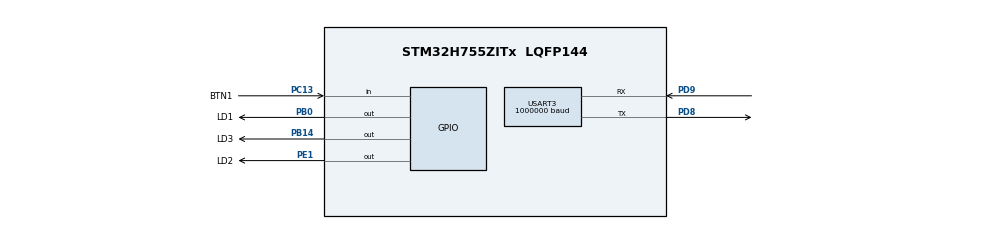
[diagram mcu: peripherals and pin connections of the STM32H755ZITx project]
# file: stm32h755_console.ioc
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CORTEX_M7.default_mode_Activation=1
CortexM4.IPs=CORTEX_M4\:I,FATFS_M4\:I,FREERTOS_M4\:I,IWDG2\:I,OPENAMP_M4\:I,PDM2PCM_M4\:I,PWR,RCC,RESMGR_UTILITY,SYS_M4\:I,USB_DEVICE_M4\:I,USB_HOST_M4\:I,VREFBUF,WWDG2\:I,GPIO,DMA,BDMA,MDMA,NVIC2\:I
CortexM7.IPs=CORTEX_M7\:I,FATFS_M7\:I,FREERTOS_M7\:I,IWDG1\:I,OPENAMP_M7\:I,PDM2PCM_M7\:I,PWR\:I,RCC\:I,RESMGR_UTILITY\:I,SYS\:I,USB_DEVICE_M7\:I,USB_HOST_M7\:I,VREFBUF\:I,WWDG1\:I,GPIO\:I,DMA\:I,BDMA\:I,MDMA\:I,NVIC1\:I,USART3\:I,TIM1\:I,TIM2\:I
CortexM7.Pins=PC13,PB0,PB14,PE1
Dma.Request0=USART3_TX
Dma.USART3_TX.0.Instance=DMA1_Stream0
Dma.USART3_TX.0.Direction=DMA_MEMORY_TO_PERIPH
Dma.USART3_TX.0.PeriphInc=DMA_PINC_DISABLE
Dma.USART3_TX.0.MemInc=DMA_MINC_ENABLE
Dma.USART3_TX.0.PeriphDataAlignment=DMA_PDATAALIGN_BYTE
Dma.USART3_TX.0.MemDataAlignment=DMA_MDATAALIGN_BYTE
Dma.USART3_TX.0.Mode=DMA_NORMAL
Dma.USART3_TX.0.Priority=DMA_PRIORITY_LOW
Dma.USART3_TX.0.FIFOMode=DMA_FIFOMODE_DISABLE
Mcu.Family=STM32H7
Mcu.Name=STM32H755ZITx
Mcu.Package=LQFP144
NVIC1.DMA1_Stream0_IRQn=true\:5\:0\:false\:false\:true\:true\:true\:true
NVIC1.FPU_IRQn=true\:0\:0\:false\:false\:true\:true\:false\:true
NVIC1.PriorityGroup=NVIC_PRIORITYGROUP_4
NVIC1.RCC_IRQn=true\:0\:0\:false\:false\:true\:true\:false\:true
NVIC1.USART3_IRQn=true\:0\:0\:false\:false\:true\:true\:true\:true
NVIC2.PriorityGroup=NVIC_PRIORITYGROUP_4
PB0.GPIO_Label=LD1
PB0.PinAttribute=CortexM7
PB0.Signal=GPIO_Output
PB14.GPIO_Label=LD3
PB14.PinAttribute=CortexM7
PB14.Signal=GPIO_Output
PC13.GPIO_Label=BTN1
PC13.PinAttribute=CortexM7
PC13.Signal=GPIO_Input
PD8.Mode=Asynchronous
PD8.PinAttribute=CortexM7
PD8.Signal=USART3_TX
PD9.Mode=Asynchronous
PD9.PinAttribute=CortexM7
PD9.Signal=USART3_RX
PE1.GPIO_Label=LD2
PE1.PinAttribute=CortexM7
PE1.Signal=GPIO_Output
ProjectManager.HeapSize=M4-0x200,M7-0x200
ProjectManager.StackSize=M4-0x400,M7-0x4000
ProjectManager.TargetToolchain=CMake
RCC.ADCFreq_Value=32000000
RCC.APB1Freq_Value=25000000
RCC.APB2Freq_Value=50000000
RCC.APB3Freq_Value=50000000
RCC.APB4Freq_Value=50000000
RCC.CortexFreq_Value=400000000
RCC.D2PPRE1=RCC_APB1_DIV2
RCC.DIVM1=4
RCC.DIVM2=4
RCC.DIVM3=4
RCC.DIVN1=50
RCC.DIVN2=16
RCC.DIVN3=16
RCC.HSE_VALUE=8000000
RCC.HCLKFreq_Value=50000000
RCC.HPRE=RCC_HCLK_DIV8
RCC.PLLSourceVirtual=RCC_PLLSOURCE_HSI
RCC.SYSCLKFreq_VALUE=400000000
RCC.SYSCLKSource=RCC_SYSCLKSOURCE_PLLCLK
RCC.USBFreq_Value=400000000
SYS.userName=SYS_M7
USART3.BaudRate=1000000
USART3.VirtualMode-Asynchronous=VM_ASYNC
VP_SYS_M4_VS_Systick.Mode=SysTick
board=custom

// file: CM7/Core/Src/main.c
/* USER CODE BEGIN Header */
/**
  ******************************************************************************
  * @file           : main.c
  * @brief          : Main program body
  ******************************************************************************
  * @attention
  *
  * Copyright (c) 2026 STMicroelectronics.
  * All rights reserved.
  *
  * This software is licensed under terms that can be found in the LICENSE file
  * in the root directory of this software component.
  * If no LICENSE file comes with this software, it is provided AS-IS.
  *
  ******************************************************************************
  */
/* USER CODE END Header */
#include "main.h"

/* USER CODE BEGIN PD */

/* DUAL_CORE_BOOT_SYNC_SEQUENCE: Define for dual core boot synchronization    */
/*                             demonstration code based on hardware semaphore */
/* This define is present in both CM7/CM4 projects                            */
/* To comment when developping/debugging on a single core                     */
#define DUAL_CORE_BOOT_SYNC_SEQUENCE

#if defined(DUAL_CORE_BOOT_SYNC_SEQUENCE)
#ifndef HSEM_ID_0
#define HSEM_ID_0 (0U) /* HW semaphore 0*/
#endif
#endif /* DUAL_CORE_BOOT_SYNC_SEQUENCE */

/* USER CODE END PD */

UART_HandleTypeDef huart3;

void SystemClock_Config(void);
static void MPU_Config(void);
static void MX_GPIO_Init(void);
static void MX_DMA_Init(void);
static void MX_USART3_UART_Init(void);
/* USER CODE BEGIN PFP */
void DaveOS_Run(void);

/* USER CODE END PFP */

int main(void)
{

/* USER CODE BEGIN Boot_Mode_Sequence_0 */
#if defined(DUAL_CORE_BOOT_SYNC_SEQUENCE)
  int32_t timeout;
#endif /* DUAL_CORE_BOOT_SYNC_SEQUENCE */
/* USER CODE END Boot_Mode_Sequence_0 */

  /* MPU Configuration--------------------------------------------------------*/
  MPU_Config();

/* USER CODE BEGIN Boot_Mode_Sequence_1 */
#if defined(DUAL_CORE_BOOT_SYNC_SEQUENCE)
  /* Wait until CPU2 boots and enters in stop mode or timeout*/
  timeout = 0xFFFF;
  while((__HAL_RCC_GET_FLAG(RCC_FLAG_D2CKRDY) != RESET) && (timeout-- > 0));
  if ( timeout < 0 )
  {
  Error_Handler();
  }
#endif /* DUAL_CORE_BOOT_SYNC_SEQUENCE */
/* USER CODE END Boot_Mode_Sequence_1 */
  /* MCU Configuration--------------------------------------------------------*/

  /* Reset of all peripherals, Initializes the Flash interface and the Systick. */
  HAL_Init();

  /* Configure the system clock */
  SystemClock_Config();
/* USER CODE BEGIN Boot_Mode_Sequence_2 */
#if defined(DUAL_CORE_BOOT_SYNC_SEQUENCE)
/* When system initialization is finished, Cortex-M7 will release Cortex-M4 by means of
HSEM notification */
/*HW semaphore Clock enable*/
__HAL_RCC_HSEM_CLK_ENABLE();
/*Take HSEM */
HAL_HSEM_FastTake(HSEM_ID_0);
/*Release HSEM in order to notify the CPU2(CM4)*/
HAL_HSEM_Release(HSEM_ID_0,0);
/* wait until CPU2 wakes up from stop mode */
timeout = 0xFFFF;
while((__HAL_RCC_GET_FLAG(RCC_FLAG_D2CKRDY) == RESET) && (timeout-- > 0));
if ( timeout < 0 )
{
Error_Handler();
}
#endif /* DUAL_CORE_BOOT_SYNC_SEQUENCE */
/* USER CODE END Boot_Mode_Sequence_2 */

  /* Initialize all configured peripherals */
  MX_GPIO_Init();
  MX_DMA_Init();
  MX_USART3_UART_Init();
  /* USER CODE BEGIN 2 */
  DaveOS_Run();

  /* USER CODE END 2 */

  /* Infinite loop */
  while (1)
  {

  }
}

void SystemClock_Config(void)
{
  RCC_OscInitTypeDef RCC_OscInitStruct = {0};
  RCC_ClkInitTypeDef RCC_ClkInitStruct = {0};

  /** Supply configuration update enable
  */
  HAL_PWREx_ConfigSupply(PWR_DIRECT_SMPS_SUPPLY);

  /** Configure the main internal regulator output voltage
  */
  __HAL_PWR_VOLTAGESCALING_CONFIG(PWR_REGULATOR_VOLTAGE_SCALE1);

  while(!__HAL_PWR_GET_FLAG(PWR_FLAG_VOSRDY)) {}

  /** Initializes the RCC Oscillators according to the specified parameters
  * in the RCC_OscInitTypeDef structure.
  */
  RCC_OscInitStruct.OscillatorType = RCC_OSCILLATORTYPE_HSI;
  RCC_OscInitStruct.HSIState = RCC_HSI_DIV1;
  RCC_OscInitStruct.HSICalibrationValue = RCC_HSICALIBRATION_DEFAULT;
  RCC_OscInitStruct.PLL.PLLState = RCC_PLL_ON;
  RCC_OscInitStruct.PLL.PLLSource = RCC_PLLSOURCE_HSI;
  RCC_OscInitStruct.PLL.PLLM = 4;
  RCC_OscInitStruct.PLL.PLLN = 50;
  RCC_OscInitStruct.PLL.PLLP = 2;
  RCC_OscInitStruct.PLL.PLLQ = 2;
  RCC_OscInitStruct.PLL.PLLR = 2;
  RCC_OscInitStruct.PLL.PLLRGE = RCC_PLL1VCIRANGE_3;
  RCC_OscInitStruct.PLL.PLLVCOSEL = RCC_PLL1VCOWIDE;
  RCC_OscInitStruct.PLL.PLLFRACN = 0;
  if (HAL_RCC_OscConfig(&RCC_OscInitStruct) != HAL_OK)
  {
    Error_Handler();
  }

  /** Initializes the CPU, AHB and APB buses clocks
  */
  RCC_ClkInitStruct.ClockType = RCC_CLOCKTYPE_HCLK|RCC_CLOCKTYPE_SYSCLK
                              |RCC_CLOCKTYPE_PCLK1|RCC_CLOCKTYPE_PCLK2
                              |RCC_CLOCKTYPE_D3PCLK1|RCC_CLOCKTYPE_D1PCLK1;
  RCC_ClkInitStruct.SYSCLKSource = RCC_SYSCLKSOURCE_PLLCLK;
  RCC_ClkInitStruct.SYSCLKDivider = RCC_SYSCLK_DIV1;
  RCC_ClkInitStruct.AHBCLKDivider = RCC_HCLK_DIV8;
  RCC_ClkInitStruct.APB3CLKDivider = RCC_APB3_DIV1;
  RCC_ClkInitStruct.APB1CLKDivider = RCC_APB1_DIV2;
  RCC_ClkInitStruct.APB2CLKDivider = RCC_APB2_DIV1;
  RCC_ClkInitStruct.APB4CLKDivider = RCC_APB4_DIV1;

  if (HAL_RCC_ClockConfig(&RCC_ClkInitStruct, FLASH_LATENCY_0) != HAL_OK)
  {
    Error_Handler();
  }
}

static void MX_USART3_UART_Init(void)
{

  huart3.Instance = USART3;
  huart3.Init.BaudRate = 1000000;
  huart3.Init.WordLength = UART_WORDLENGTH_8B;
  huart3.Init.StopBits = UART_STOPBITS_1;
  huart3.Init.Parity = UART_PARITY_NONE;
  huart3.Init.Mode = UART_MODE_TX_RX;
  huart3.Init.HwFlowCtl = UART_HWCONTROL_NONE;
  huart3.Init.OverSampling = UART_OVERSAMPLING_16;
  huart3.Init.OneBitSampling = UART_ONE_BIT_SAMPLE_DISABLE;
  huart3.Init.ClockPrescaler = UART_PRESCALER_DIV1;
  huart3.AdvancedInit.AdvFeatureInit = UART_ADVFEATURE_NO_INIT;
  if (HAL_UART_Init(&huart3) != HAL_OK)
  {
    Error_Handler();
  }
  if (HAL_UARTEx_SetTxFifoThreshold(&huart3, UART_TXFIFO_THRESHOLD_1_8) != HAL_OK)
  {
    Error_Handler();
  }
  if (HAL_UARTEx_SetRxFifoThreshold(&huart3, UART_RXFIFO_THRESHOLD_1_8) != HAL_OK)
  {
    Error_Handler();
  }
  if (HAL_UARTEx_DisableFifoMode(&huart3) != HAL_OK)
  {
    Error_Handler();
  }

}

static void MX_GPIO_Init(void)
{
  GPIO_InitTypeDef GPIO_InitStruct = {0};

  /* GPIO Ports Clock Enable */
  __HAL_RCC_GPIOC_CLK_ENABLE();
  __HAL_RCC_GPIOB_CLK_ENABLE();
  __HAL_RCC_GPIOD_CLK_ENABLE();
  __HAL_RCC_GPIOE_CLK_ENABLE();

  /*Configure GPIO pin Output Level */
  HAL_GPIO_WritePin(GPIOB, LD1_Pin|LD3_Pin, GPIO_PIN_RESET);

  /*Configure GPIO pin Output Level */
  HAL_GPIO_WritePin(LD2_GPIO_Port, LD2_Pin, GPIO_PIN_RESET);

  /*Configure GPIO pin : BTN1_Pin */
  GPIO_InitStruct.Pin = BTN1_Pin;
  GPIO_InitStruct.Mode = GPIO_MODE_INPUT;
  GPIO_InitStruct.Pull = GPIO_NOPULL;
  HAL_GPIO_Init(BTN1_GPIO_Port, &GPIO_InitStruct);

  /*Configure GPIO pins : LD1_Pin LD3_Pin */
  GPIO_InitStruct.Pin = LD1_Pin|LD3_Pin;
  GPIO_InitStruct.Mode = GPIO_MODE_OUTPUT_PP;
  GPIO_InitStruct.Pull = GPIO_NOPULL;
  GPIO_InitStruct.Speed = GPIO_SPEED_FREQ_LOW;
  HAL_GPIO_Init(GPIOB, &GPIO_InitStruct);

  /*Configure GPIO pin : LD2_Pin */
  GPIO_InitStruct.Pin = LD2_Pin;
  GPIO_InitStruct.Mode = GPIO_MODE_OUTPUT_PP;
  GPIO_InitStruct.Pull = GPIO_NOPULL;
  GPIO_InitStruct.Speed = GPIO_SPEED_FREQ_LOW;
  HAL_GPIO_Init(LD2_GPIO_Port, &GPIO_InitStruct);

}

/* DMA clock and NVIC must be ready before the UART MSP links its TX stream. */
static void MX_DMA_Init(void)
{
  __HAL_RCC_DMA1_CLK_ENABLE();
  HAL_NVIC_SetPriority(DMA1_Stream0_IRQn, 5, 0);
  HAL_NVIC_EnableIRQ(DMA1_Stream0_IRQn);
  /* USER CODE BEGIN DMA_Init 1 */
  __HAL_RCC_DMA1_CLK_SLEEP_ENABLE();
  __HAL_RCC_D1SRAM1_CLK_SLEEP_ENABLE();
  /* USER CODE END DMA_Init 1 */
}

 /* MPU Configuration */

void MPU_Config(void)
{
  MPU_Region_InitTypeDef MPU_InitStruct = {0};

  /* Disables the MPU */
  HAL_MPU_Disable();

  /** Initializes and configures the Region and the memory to be protected
  */
  MPU_InitStruct.Enable = MPU_REGION_ENABLE;
  MPU_InitStruct.Number = MPU_REGION_NUMBER0;
  MPU_InitStruct.BaseAddress = 0x0;
  MPU_InitStruct.Size = MPU_REGION_SIZE_4GB;
  MPU_InitStruct.SubRegionDisable = 0x87;
  MPU_InitStruct.TypeExtField = MPU_TEX_LEVEL0;
  MPU_InitStruct.AccessPermission = MPU_REGION_NO_ACCESS;
  MPU_InitStruct.DisableExec = MPU_INSTRUCTION_ACCESS_DISABLE;
  MPU_InitStruct.IsShareable = MPU_ACCESS_SHAREABLE;
  MPU_InitStruct.IsCacheable = MPU_ACCESS_NOT_CACHEABLE;
  MPU_InitStruct.IsBufferable = MPU_ACCESS_NOT_BUFFERABLE;

  HAL_MPU_ConfigRegion(&MPU_InitStruct);
  /* Enables the MPU */
  HAL_MPU_Enable(MPU_PRIVILEGED_DEFAULT);

}

void Error_Handler(void)
{
  __disable_irq();
  while (1)
  {
  }
}
